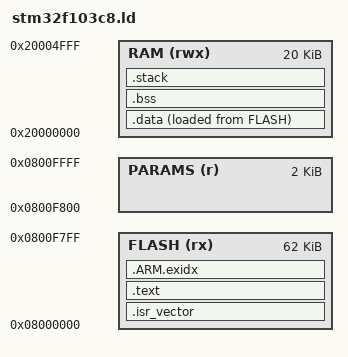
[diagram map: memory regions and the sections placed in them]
ENTRY(Reset_Handler)
MEMORY {
 FLASH (rx) : ORIGIN = 0x08000000, LENGTH = 62K
 PARAMS (r) : ORIGIN = 0x0800F800, LENGTH = 2K
 RAM (rwx) : ORIGIN = 0x20000000, LENGTH = 20K
}
_estack = ORIGIN(RAM) + LENGTH(RAM);
SECTIONS {
 .isr_vector : { KEEP(*(.isr_vector)) } > FLASH
 .text : { *(.text*) *(.rodata*) . = ALIGN(4); } > FLASH
 .ARM.exidx : { *(.ARM.exidx*) } > FLASH
 _sidata = LOADADDR(.data);
 .data : { . = ALIGN(4); _sdata = .; *(.data*) . = ALIGN(4); _edata = .; } > RAM AT > FLASH
 .bss (NOLOAD) : { . = ALIGN(4); _sbss = .; *(.bss*) *(COMMON) . = ALIGN(4); _ebss = .; } > RAM
 .stack (NOLOAD) : { . = ALIGN(8); . += 2048; } > RAM
 ASSERT(_ebss + 2048 <= _estack, "RAM overlaps minimum 2 KiB stack")
}
